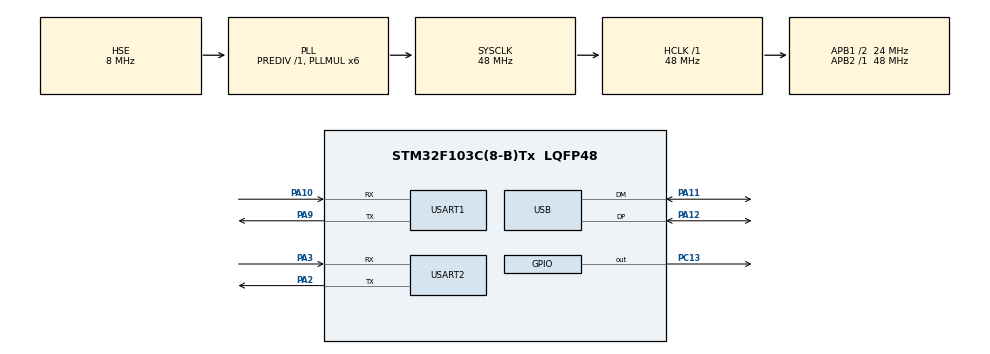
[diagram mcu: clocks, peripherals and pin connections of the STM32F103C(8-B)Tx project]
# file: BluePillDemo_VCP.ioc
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FREERTOS.Tasks01=defaultTask,0,256,StartDefaultTask,Default,NULL,Dynamic,NULL,NULL;myTask02,-3,128,StartTask02,Default,NULL,Dynamic,NULL,NULL;myTask03,-3,128,StartTask03,Default,NULL,Dynamic,NULL,NULL
FREERTOS.configUSE_NEWLIB_REENTRANT=1
Mcu.Family=STM32F1
Mcu.Name=STM32F103C(8-B)Tx
Mcu.Package=LQFP48
NVIC.PriorityGroup=NVIC_PRIORITYGROUP_4
NVIC.TIM4_IRQn=true\:15\:0\:false\:false\:true\:false\:false\:true\:true
NVIC.TimeBase=TIM4_IRQn
NVIC.TimeBaseIP=TIM4
NVIC.USART1_IRQn=true\:5\:0\:false\:false\:true\:true\:true\:true\:true
NVIC.USART2_IRQn=true\:5\:0\:false\:false\:true\:true\:true\:true\:true
NVIC.USB_HP_CAN1_TX_IRQn=true\:5\:0\:false\:false\:true\:true\:true\:true\:true
NVIC.USB_LP_CAN1_RX0_IRQn=true\:5\:0\:false\:false\:true\:true\:true\:true\:true
PA10.Mode=Asynchronous
PA10.Signal=USART1_RX
PA11.Mode=Device
PA11.Signal=USB_DM
PA12.Mode=Device
PA12.Signal=USB_DP
PA13.Mode=Serial_Wire
PA13.Signal=SYS_JTMS-SWDIO
PA14.Mode=Serial_Wire
PA14.Signal=SYS_JTCK-SWCLK
PA2.Mode=Asynchronous
PA2.Signal=USART2_TX
PA3.Mode=Asynchronous
PA3.Signal=USART2_RX
PA9.Mode=Asynchronous
PA9.Signal=USART1_TX
PC13-TAMPER-RTC.PinState=GPIO_PIN_SET
PC13-TAMPER-RTC.Signal=GPIO_Output
PD0-OSC_IN.Mode=HSE-External-Oscillator
PD0-OSC_IN.Signal=RCC_OSC_IN
PD1-OSC_OUT.Mode=HSE-External-Oscillator
PD1-OSC_OUT.Signal=RCC_OSC_OUT
ProjectManager.HeapSize=0x200
ProjectManager.StackSize=0x400
ProjectManager.TargetToolchain=STM32CubeIDE
RCC.AHBFreq_Value=48000000
RCC.APB1CLKDivider=RCC_HCLK_DIV2
RCC.APB1Freq_Value=24000000
RCC.APB1TimFreq_Value=48000000
RCC.APB2Freq_Value=48000000
RCC.APB2TimFreq_Value=48000000
RCC.HCLKFreq_Value=48000000
RCC.PLLMUL=RCC_PLL_MUL6
RCC.PLLSourceVirtual=RCC_PLLSOURCE_HSE
RCC.SYSCLKFreq_VALUE=48000000
RCC.SYSCLKSource=RCC_SYSCLKSOURCE_PLLCLK
RCC.USBFreq_Value=48000000
USART1.VirtualMode=VM_ASYNC
USART2.VirtualMode=VM_ASYNC
USB_DEVICE.CLASS_NAME_FS=CDC
USB_DEVICE.VirtualMode=Cdc
USB_DEVICE.VirtualModeFS=Cdc_FS
VP_FREERTOS_VS_CMSIS_V1.Mode=CMSIS_V1
VP_SYS_VS_tim4.Mode=TIM4
VP_USB_DEVICE_VS_USB_DEVICE_CDC_FS.Mode=CDC_FS
board=custom

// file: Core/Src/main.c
/* USER CODE BEGIN Header */
/**
  ******************************************************************************
  * @file           : main.c
  * @brief          : Main program body
  ******************************************************************************
  * @attention
  *
  * <h2><center>&copy; Copyright (c) 2020 STMicroelectronics.
  * All rights reserved.</center></h2>
  *
  * This software component is licensed by ST under BSD 3-Clause license,
  * the "License"; You may not use this file except in compliance with the
  * License. You may obtain a copy of the License at:
  *                        opensource.org/licenses/BSD-3-Clause
  *
  ******************************************************************************
  */
/* USER CODE END Header */
#include "main.h"
#include "cmsis_os.h"
#include "usart.h"
#include "usb_device.h"
#include "gpio.h"

/* USER CODE BEGIN Includes */
#include "usbd_cdc_if.h"
/* USER CODE END Includes */

/* USER CODE BEGIN PV */
extern UART_HandleTypeDef huart1;
extern UART_HandleTypeDef huart2;

/* USER CODE END PV */

void SystemClock_Config(void);
void MX_FREERTOS_Init(void);

/* USER CODE BEGIN 0 */
int _write(int file, char *ptr, int len)
{
  HAL_UART_Transmit(&huart1, (uint8_t*)ptr, len, HAL_MAX_DELAY);
  return len;
}

/* USER CODE END 0 */

int main(void)
{

  /* MCU Configuration--------------------------------------------------------*/

  /* Reset of all peripherals, Initializes the Flash interface and the Systick. */
  HAL_Init();

  /* Configure the system clock */
  SystemClock_Config();

  /* Initialize all configured peripherals */
  MX_GPIO_Init();
  MX_USART2_UART_Init();
  MX_USART1_UART_Init();

  /* Call init function for freertos objects (in cmsis_os2.c) */
  MX_FREERTOS_Init();

  /* Start scheduler */
  osKernelStart();

  /* We should never get here as control is now taken by the scheduler */

  /* Infinite loop */
  /* USER CODE BEGIN WHILE */

  // Start UART reception in interrupt mode

  while (1)
  {
    /* USER CODE END WHILE */

    /* USER CODE BEGIN 3 */

		HAL_Delay(1);

  }
  /* USER CODE END 3 */
}

void SystemClock_Config(void)
{
  RCC_OscInitTypeDef RCC_OscInitStruct = {0};
  RCC_ClkInitTypeDef RCC_ClkInitStruct = {0};
  RCC_PeriphCLKInitTypeDef PeriphClkInit = {0};

  /** Initializes the RCC Oscillators according to the specified parameters
  * in the RCC_OscInitTypeDef structure.
  */
  RCC_OscInitStruct.OscillatorType = RCC_OSCILLATORTYPE_HSE;
  RCC_OscInitStruct.HSEState = RCC_HSE_ON;
  RCC_OscInitStruct.HSEPredivValue = RCC_HSE_PREDIV_DIV1;
  RCC_OscInitStruct.HSIState = RCC_HSI_ON;
  RCC_OscInitStruct.PLL.PLLState = RCC_PLL_ON;
  RCC_OscInitStruct.PLL.PLLSource = RCC_PLLSOURCE_HSE;
  RCC_OscInitStruct.PLL.PLLMUL = RCC_PLL_MUL6;
  if (HAL_RCC_OscConfig(&RCC_OscInitStruct) != HAL_OK)
  {
    Error_Handler();
  }

  /** Initializes the CPU, AHB and APB buses clocks
  */
  RCC_ClkInitStruct.ClockType = RCC_CLOCKTYPE_HCLK|RCC_CLOCKTYPE_SYSCLK
                              |RCC_CLOCKTYPE_PCLK1|RCC_CLOCKTYPE_PCLK2;
  RCC_ClkInitStruct.SYSCLKSource = RCC_SYSCLKSOURCE_PLLCLK;
  RCC_ClkInitStruct.AHBCLKDivider = RCC_SYSCLK_DIV1;
  RCC_ClkInitStruct.APB1CLKDivider = RCC_HCLK_DIV2;
  RCC_ClkInitStruct.APB2CLKDivider = RCC_HCLK_DIV1;

  if (HAL_RCC_ClockConfig(&RCC_ClkInitStruct, FLASH_LATENCY_1) != HAL_OK)
  {
    Error_Handler();
  }
  PeriphClkInit.PeriphClockSelection = RCC_PERIPHCLK_USB;
  PeriphClkInit.UsbClockSelection = RCC_USBCLKSOURCE_PLL;
  if (HAL_RCCEx_PeriphCLKConfig(&PeriphClkInit) != HAL_OK)
  {
    Error_Handler();
  }
}

void HAL_TIM_PeriodElapsedCallback(TIM_HandleTypeDef *htim)
{
  if (htim->Instance == TIM4) {
    HAL_IncTick();
  }
}

void Error_Handler(void)
{
}

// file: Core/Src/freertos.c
/* USER CODE BEGIN Header */
/**
  ******************************************************************************
  * File Name          : freertos.c
  * Description        : Code for freertos applications
  ******************************************************************************
  * @attention
  *
  * Copyright (c) 2024 STMicroelectronics.
  * All rights reserved.
  *
  * This software is licensed under terms that can be found in the LICENSE file
  * in the root directory of this software component.
  * If no LICENSE file comes with this software, it is provided AS-IS.
  *
  ******************************************************************************
  */
/* USER CODE END Header */

#include "FreeRTOS.h"
#include "task.h"
#include "main.h"
#include "cmsis_os.h"

osThreadId defaultTaskHandle;
osThreadId myTask02Handle;
osThreadId myTask03Handle;

void StartDefaultTask(void const * argument);
void StartTask02(void const * argument);
void StartTask03(void const * argument);

extern void MX_USB_DEVICE_Init(void);
void MX_FREERTOS_Init(void); /* (MISRA C 2004 rule 8.1) */

/* GetIdleTaskMemory prototype (linked to static allocation support) */
void vApplicationGetIdleTaskMemory( StaticTask_t **ppxIdleTaskTCBBuffer, StackType_t **ppxIdleTaskStackBuffer, uint32_t *pulIdleTaskStackSize );

/* USER CODE BEGIN GET_IDLE_TASK_MEMORY */
static StaticTask_t xIdleTaskTCBBuffer;
static StackType_t xIdleStack[configMINIMAL_STACK_SIZE];

void vApplicationGetIdleTaskMemory( StaticTask_t **ppxIdleTaskTCBBuffer, StackType_t **ppxIdleTaskStackBuffer, uint32_t *pulIdleTaskStackSize )
{
  *ppxIdleTaskTCBBuffer = &xIdleTaskTCBBuffer;
  *ppxIdleTaskStackBuffer = &xIdleStack[0];
  *pulIdleTaskStackSize = configMINIMAL_STACK_SIZE;
  /* place for user code */
}
/* USER CODE END GET_IDLE_TASK_MEMORY */

void MX_FREERTOS_Init(void) {

  /* Create the thread(s) */
  /* definition and creation of defaultTask */
  osThreadDef(defaultTask, StartDefaultTask, osPriorityNormal, 0, 256);
  defaultTaskHandle = osThreadCreate(osThread(defaultTask), NULL);

  /* definition and creation of myTask02 */
  osThreadDef(myTask02, StartTask02, osPriorityIdle, 0, 128);
  myTask02Handle = osThreadCreate(osThread(myTask02), NULL);

  /* definition and creation of myTask03 */
  osThreadDef(myTask03, StartTask03, osPriorityIdle, 0, 128);
  myTask03Handle = osThreadCreate(osThread(myTask03), NULL);

}

void StartDefaultTask(void const * argument)
{
  /* init code for USB_DEVICE */
  MX_USB_DEVICE_Init();
  /* USER CODE BEGIN StartDefaultTask */
  /* Infinite loop */
  for(;;)
  {
	//HAL_GPIO_TogglePin(GPIOC, GPIO_PIN_13);
	osDelay(1);
  }
  /* USER CODE END StartDefaultTask */
}

void StartTask02(void const * argument)
{
  for(;;)
  {
    osDelay(1);
  }
}

void StartTask03(void const * argument)
{
  for(;;)
  {
    osDelay(1);
  }
}
